# MSP432E411Y register map
Vendor: Texas Instruments; File version: 3.200
CPU: CM4 r1p2, little endian, no MPU, no FPU, 0x3 interrupt priority bits, 0x0 interrupts
Registers are 32-bit, read-write, no defined reset value unless marked. A register's access mark holds for its fields unless they carry their own. Offsets are from the block's base; [hi:lo] are bit positions.

## LCD0 — Register map for LCD0 peripheral
Base 0x44050000; register names take the prefix LCD0
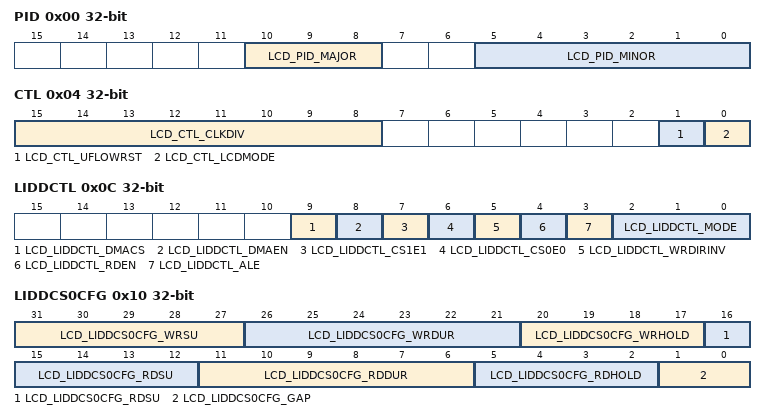
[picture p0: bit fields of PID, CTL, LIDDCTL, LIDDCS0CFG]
0x00 PID — LCD PID Register Format
  [10:8] LCD_PID_MAJOR — Major Release Number
  [5:0] LCD_PID_MINOR — Minor Release Number
0x04 CTL — LCD Control
  [15:8] LCD_CTL_CLKDIV — Clock Divisor
  [1] LCD_CTL_UFLOWRST — Underflow Restart
  [0] LCD_CTL_LCDMODE — LCD Mode Select
0x0C LIDDCTL — LCD LIDD Control
  [9] LCD_LIDDCTL_DMACS — CS0/CS1 Select for LIDD DMA Writes
  [8] LCD_LIDDCTL_DMAEN — LIDD DMA Enable
  [7] LCD_LIDDCTL_CS1E1 — Chip Select 1 (CS1)/Enable 1(E1) Polarity Control
  [6] LCD_LIDDCTL_CS0E0 — Chip Select 0 (CS0)/Enable 0 (E0) Polarity Control
  [5] LCD_LIDDCTL_WRDIRINV — Write Strobe (WR) /Direction (DIR) Polarity Control
  [4] LCD_LIDDCTL_RDEN — Read Strobe (RD) /Direct Enable (EN) Polarity Control
  [3] LCD_LIDDCTL_ALE — Address Latch Enable (ALE) Polarity Control
  [2:0] LCD_LIDDCTL_MODE — LIDD Mode Select
    0=LCD_LIDDCTL_MODE_SYNCM68 (Synchronous Motorola 6800 Mode); 1=LCD_LIDDCTL_MODE_ASYNCM68 (Asynchronous Motorola 6800 Mode); 2=LCD_LIDDCTL_MODE_SYNCM80 (Synchronous Intel 8080 mode); 3=LCD_LIDDCTL_MODE_ASYNCM80 (Asynchronous Intel 8080 mode); 4=LCD_LIDDCTL_MODE_ASYNCHIT (Asynchronous Hitachi mode)
0x10 LIDDCS0CFG — LCD LIDD CS0 Configuration
  [31:27] LCD_LIDDCS0CFG_WRSU — Write Strobe (WR) Set-Up Cycles
  [26:21] LCD_LIDDCS0CFG_WRDUR — Write Strobe (WR) Duration Cycles
  [20:17] LCD_LIDDCS0CFG_WRHOLD — Write Strobe (WR) Hold cycles
  [16:12] LCD_LIDDCS0CFG_RDSU — Read Strobe (RD) Set-Up cycles
  [11:6] LCD_LIDDCS0CFG_RDDUR — Read Strobe (RD) Duration cycles
  [5:2] LCD_LIDDCS0CFG_RDHOLD — Read Strobe (RD) Hold cycles
  [1:0] LCD_LIDDCS0CFG_GAP — Field value defines the number of LCDMCLK cycles (GAP +1) between the end of one CS0 (LCDAC) device access and the start of another CS0 (LCDAC) device access unless the two accesses are both reads
0x14 LIDDCS0ADDR — LIDD CS0 Read/Write Address
  [15:0] LCD_LIDDCS0ADDR_CS0ADDR — LCD Address
0x18 LIDDCS0DATA — LIDD CS0 Data Read/Write Initiation
  [15:0] LCD_LIDDCS0DATA_CS0DATA — LCD Data Read/Write
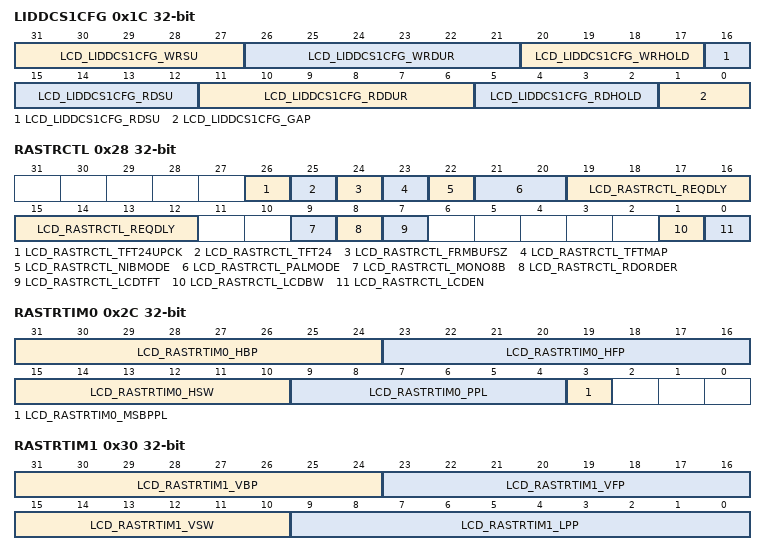
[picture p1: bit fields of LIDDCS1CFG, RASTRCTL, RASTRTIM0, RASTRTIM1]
0x1C LIDDCS1CFG — LIDD CS1 Configuration
  [31:27] LCD_LIDDCS1CFG_WRSU — Write Strobe (WR) Set-Up Cycles
  [26:21] LCD_LIDDCS1CFG_WRDUR — Write Strobe (WR) Duration Cycles
  [20:17] LCD_LIDDCS1CFG_WRHOLD — Write Strobe (WR) Hold cycles
  [16:12] LCD_LIDDCS1CFG_RDSU — Read Strobe (RD) Set-Up cycles
  [11:6] LCD_LIDDCS1CFG_RDDUR — Read Strobe (RD) Duration cycles
  [5:2] LCD_LIDDCS1CFG_RDHOLD — Read Strobe (RD) Hold cycles
  [1:0] LCD_LIDDCS1CFG_GAP — Field value defines the number of LCDMCLK cycles (GAP + 1) between the end of one CS1 (LCDAC) device access and the start of another CS0 (LCDAC) device access unless the two accesses are both reads
0x20 LIDDCS1ADDR — LIDD CS1 Address Read/Write Initiation
  [15:0] LCD_LIDDCS1ADDR_CS1ADDR — LCD Address Bus
0x24 LIDDCS1DATA — LIDD CS1 Data Read/Write Initiation
  [15:0] LCD_LIDDCS1DATA_CS0DATA — LCD Data Read/Write Initiation
0x28 RASTRCTL — LCD Raster Control
  [26] LCD_RASTRCTL_TFT24UPCK — 24-bit TFT Mode Packing
  [25] LCD_RASTRCTL_TFT24 — 24-Bit TFT Mode
  [24] LCD_RASTRCTL_FRMBUFSZ — Frame Buffer Select
  [23] LCD_RASTRCTL_TFTMAP — TFT Mode Alternate Signal Mapping for Palettized Framebuffer
  [22] LCD_RASTRCTL_NIBMODE — Nibble Mode
  [21:20] LCD_RASTRCTL_PALMODE — Pallette Loading Mode
    0=LCD_RASTRCTL_PALMODE_PALDAT (Palette and data loading, reset value); 1=LCD_RASTRCTL_PALMODE_PAL (Palette loading only); 2=LCD_RASTRCTL_PALMODE_DAT (Data loading only)
  [19:12] LCD_RASTRCTL_REQDLY — Palette Loading Delay
  [9] LCD_RASTRCTL_MONO8B — Mono 8-Bit
  [8] LCD_RASTRCTL_RDORDER — Raster Data Order Select
  [7] LCD_RASTRCTL_LCDTFT — LCD TFT
  [1] LCD_RASTRCTL_LCDBW — LCD Monochrome
  [0] LCD_RASTRCTL_LCDEN — LCD Controller Enable for Raster Operations
0x2C RASTRTIM0 — LCD Raster Timing 0
  [31:24] LCD_RASTRTIM0_HBP — Horizontal Back Porch Lowbits
  [23:16] LCD_RASTRTIM0_HFP — Horizontal Front Porch Lowbits
  [15:10] LCD_RASTRTIM0_HSW — Horizontal Sync Pulse Width Lowbits
  [9:4] LCD_RASTRTIM0_PPL — Pixels-per-line LSB[9:4]
  [3] LCD_RASTRTIM0_MSBPPL — Pixels-per-line MSB[10]
0x30 RASTRTIM1 — LCD Raster Timing 1
  [31:24] LCD_RASTRTIM1_VBP — Vertical Back Porch
  [23:16] LCD_RASTRTIM1_VFP — Vertical Front Porch
  [15:10] LCD_RASTRTIM1_VSW — Vertical Sync Width Pulse
  [9:0] LCD_RASTRTIM1_LPP — Lines Per Panel
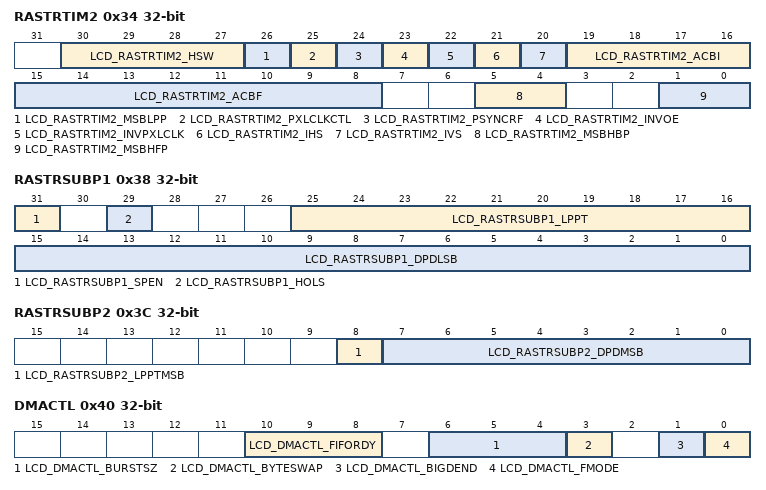
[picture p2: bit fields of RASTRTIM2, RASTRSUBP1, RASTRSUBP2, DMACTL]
0x34 RASTRTIM2 — LCD Raster Timing 2
  [30:27] LCD_RASTRTIM2_HSW — Bits 9:6 of the horizontal sync width field
  [26] LCD_RASTRTIM2_MSBLPP — MSB of Lines Per Panel
  [25] LCD_RASTRTIM2_PXLCLKCTL — Hsync/Vsync Pixel Clock Control On/Off
  [24] LCD_RASTRTIM2_PSYNCRF — Program HSYNC/VSYNC Rise or Fall
  [23] LCD_RASTRTIM2_INVOE — Invert Output Enable
  [22] LCD_RASTRTIM2_INVPXLCLK — Invert Pixel Clock
  [21] LCD_RASTRTIM2_IHS — Invert Hysync
  [20] LCD_RASTRTIM2_IVS — Invert Vsync
  [19:16] LCD_RASTRTIM2_ACBI — AC Bias Pins Transitions per Interrupt
  [15:8] LCD_RASTRTIM2_ACBF — AC Bias Pin Frequency
  [5:4] LCD_RASTRTIM2_MSBHBP — Bits 9:8 of the horizontal back porch field
  [1:0] LCD_RASTRTIM2_MSBHFP — Bits 9:8 of the horizontal front porch field
0x38 RASTRSUBP1 — LCD Raster Subpanel Display 1
  [31] LCD_RASTRSUBP1_SPEN — Sub Panel Enable
  [29] LCD_RASTRSUBP1_HOLS — High or Low Signal
  [25:16] LCD_RASTRSUBP1_LPPT — Line Per Panel Threshold
  [15:0] LCD_RASTRSUBP1_DPDLSB — Default Pixel Data LSB[15:0]
0x3C RASTRSUBP2 — LCD Raster Subpanel Display 2
  [8] LCD_RASTRSUBP2_LPPTMSB — Lines Per Panel Threshold Bit 10
  [7:0] LCD_RASTRSUBP2_DPDMSB — Default Pixel Data MSB [23:16]
0x40 DMACTL — LCD DMA Control
  [10:8] LCD_DMACTL_FIFORDY — DMA FIFO threshold
    0=8 words; 1=16 words; 2=32 words; 3=64 words; 4=128 words; 5=256 words; 6=512 words
  [6:4] LCD_DMACTL_BURSTSZ — Burst Size setting for DMA transfers (all DMA transfers are 32 bits wide):
    2=burst size of 4; 3=burst size of 8; 4=burst size of 16
  [3] LCD_DMACTL_BYTESWAP — This bit controls the bytelane ordering of the data on the output of the DMA module
  [1] LCD_DMACTL_BIGDEND — Big Endian Enable
  [0] LCD_DMACTL_FMODE — Frame Mode
0x44 DMABAFB0 — LCD DMA Frame Buffer 0 Base Address
  [31:2] LCD_DMABAFB0_FB0BA — Frame Buffer 0 Base Address pointer
0x48 DMACAFB0 — LCD DMA Frame Buffer 0 Ceiling Address
  [31:2] LCD_DMACAFB0_FB0CA — Frame Buffer 0 Ceiling Address pointer
0x4C DMABAFB1 — LCD DMA Frame Buffer 1 Base Address
  [31:2] LCD_DMABAFB1_FB1BA — Frame Buffer 1 Base Address pointer
0x50 DMACAFB1 — LCD DMA Frame Buffer 1 Ceiling Address
  [31:2] LCD_DMACAFB1_FB1CA — Frame Buffer 1 Ceiling Address pointer
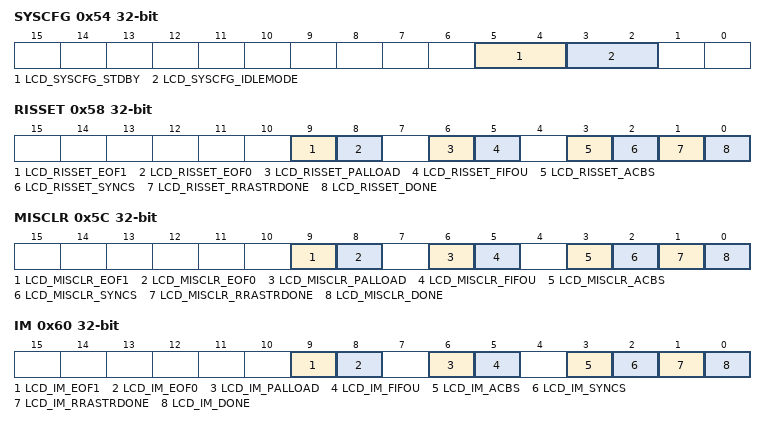
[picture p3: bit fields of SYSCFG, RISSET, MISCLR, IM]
0x54 SYSCFG — LCD System Configuration Register
  [5:4] LCD_SYSCFG_STDBY — Standby Mode
    0=LCD_SYSCFG_STDBY_FORCE (Force-standby mode: local initiator is unconditionally placed in standby state. Backup mode, for debug only); 1=LCD_SYSCFG_STDBY_NONE (No-standby mode: local initiator is unconditionally placed out of standby state. Backup mode, for debug only); 2=LCD_SYSCFG_STDBY_SMART (Smart-standby mode: local initiator standby status depends on local conditions, that is, the module's functional requirement from the initiator. IP module shall not generate (initiator-related) wakeup events)
  [3:2] LCD_SYSCFG_IDLEMODE — Idle Mode
    0=LCD_SYSCFG_IDLEMODE_FORCE (Force-idle mode: local target's idle state follows (acknowledges) the system's idle requests unconditionally, that is, regardless of the IP module's internal requirements. Backup mode, for debug only); 1=LCD_SYSCFG_IDLEMODE_NONE (No-idle mode: local target never enters idle state. Backup mode, for debug only); 2=LCD_SYSCFG_IDLEMODE_SMART (Smart-idle mode: local target's idle state eventually follows (acknowledges) the system's idle requests, depending on the IP module's internal requirements. IP module shall not generate (IRQ- or DMA-requestrelated) wakeup events)
0x58 RISSET — LCD Interrupt Raw Status and Set Register
  [9] LCD_RISSET_EOF1 — DMA End-of-Frame 1 Raw Interrupt Status and Set
  [8] LCD_RISSET_EOF0 — DMA End-of-Frame 0 Raw Interrupt Status and Set
  [6] LCD_RISSET_PALLOAD — DMA Palette Loaded Raw Interrupt Status and Set
  [5] LCD_RISSET_FIFOU — DMA FIFO Underflow Raw Interrupt Status and Set
  [3] LCD_RISSET_ACBS — AC Bias Count Raw Interrupt Status and Set
  [2] LCD_RISSET_SYNCS — Frame Synchronization Lost Raw Interrupt Status and Set
  [1] LCD_RISSET_RRASTRDONE — Raster Mode Frame Done interrupt
  [0] LCD_RISSET_DONE — Raster or LIDD Frame Done (shared, depends on whether Raster or LIDD mode enabled) Raw Interrupt Status and Set
0x5C MISCLR — LCD Interrupt Status and Clear
  [9] LCD_MISCLR_EOF1 — DMA End-of-Frame 1 Enabled Interrupt and Clear
  [8] LCD_MISCLR_EOF0 — DMA End-of-Frame 0 Raw Interrupt and Clear
  [6] LCD_MISCLR_PALLOAD — DMA Palette Loaded Enabled Interrupt and Clear
  [5] LCD_MISCLR_FIFOU — DMA FIFO Underflow Enabled Interrupt and Clear
  [3] LCD_MISCLR_ACBS — AC Bias Count Enabled Interrupt and Clear
  [2] LCD_MISCLR_SYNCS — Frame Synchronization Lost Enabled Interrupt and Clear
  [1] LCD_MISCLR_RRASTRDONE — Raster Mode Frame Done interrupt
  [0] LCD_MISCLR_DONE — Raster or LIDD Frame Done (shared, depends on whether Raster or LIDD mode enabled) Enabled Interrupt and Clear
0x60 IM — LCD Interrupt Mask
  [9] LCD_IM_EOF1 — DMA End-of-Frame 1 Interrupt Enable Set
  [8] LCD_IM_EOF0 — DMA End-of-Frame 0 Interrupt Enable Set
  [6] LCD_IM_PALLOAD — DMA Palette Loaded Interrupt Enable Set
  [5] LCD_IM_FIFOU — DMA FIFO Underflow Interrupt Enable Set
  [3] LCD_IM_ACBS — AC Bias Count Interrupt Enable Set
  [2] LCD_IM_SYNCS — Frame Synchronization Lost Interrupt Enable Set
  [1] LCD_IM_RRASTRDONE — Raster Mode Frame Done Interrupt Enable Set
  [0] LCD_IM_DONE — Raster or LIDD Frame Done (shared, depends on whether Raster or LIDD mode enabled) Interrupt Enable Set
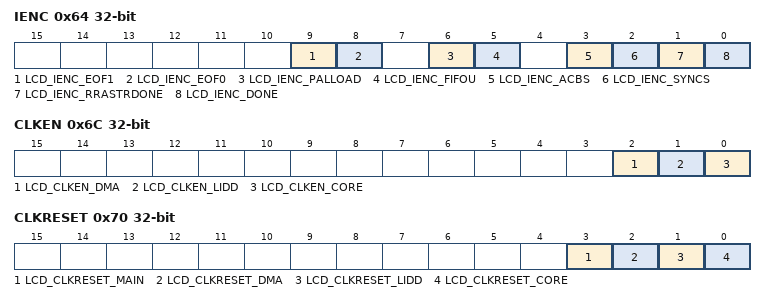
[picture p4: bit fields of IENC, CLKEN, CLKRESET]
0x64 IENC — LCD Interrupt Enable Clear
  [9] LCD_IENC_EOF1 — DMA End-of-Frame 1 Interrupt Enable Clear
  [8] LCD_IENC_EOF0 — DMA End-of-Frame 0 Interrupt Enable Clear
  [6] LCD_IENC_PALLOAD — DMA Palette Loaded Interrupt Enable Clear
  [5] LCD_IENC_FIFOU — DMA FIFO Underflow Interrupt Enable Clear
  [3] LCD_IENC_ACBS — AC Bias Count Interrupt Enable Clear
  [2] LCD_IENC_SYNCS — Frame Synchronization Lost Interrupt Enable Clear
  [1] LCD_IENC_RRASTRDONE — Raster Mode Frame Done Interrupt Enable Clear
  [0] LCD_IENC_DONE — Raster or LIDD Frame Done (shared, depends on whether Raster or LIDD mode enabled) Interrupt Enable Clear
0x6C CLKEN — LCD Clock Enable
  [2] LCD_CLKEN_DMA — DMA Clock Enable
  [1] LCD_CLKEN_LIDD — LIDD Submodule Clock Enable
  [0] LCD_CLKEN_CORE — LCD Core Clock Enable
0x70 CLKRESET — LCD Clock Resets
  [3] LCD_CLKRESET_MAIN — Software Reset for the entire LCD module
  [2] LCD_CLKRESET_DMA — Software Reset for the DMA submodule
  [1] LCD_CLKRESET_LIDD — Software Reset for the LIDD submodule (character displays)
  [0] LCD_CLKRESET_CORE — Software Reset for the Core, which encompasses the Raster Active Matrix and Passive Matrix logic
